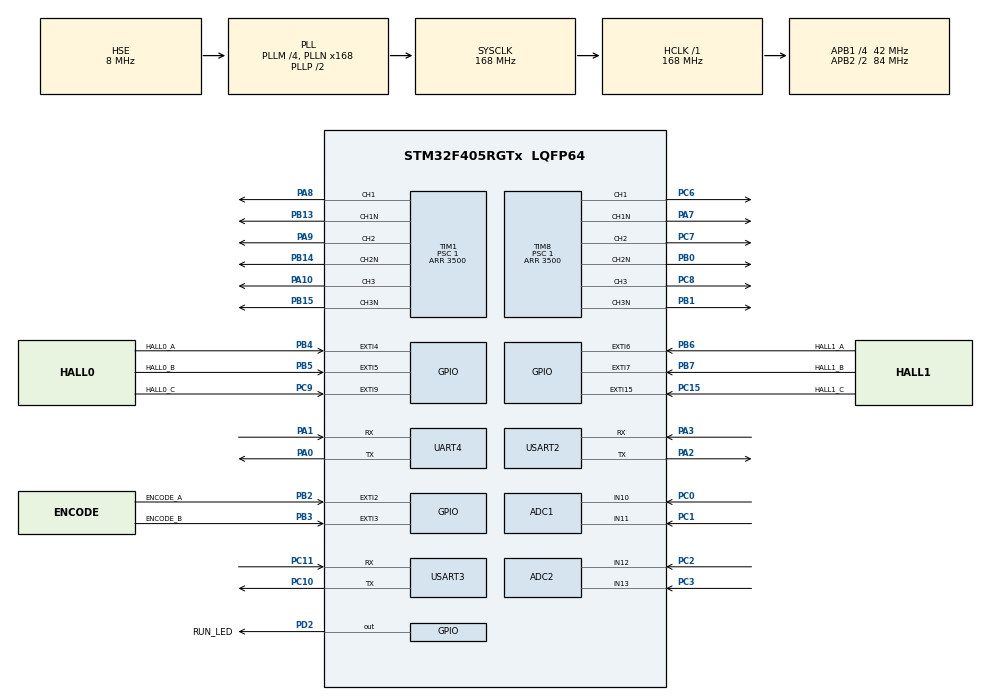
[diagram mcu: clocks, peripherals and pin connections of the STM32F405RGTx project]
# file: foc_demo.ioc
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ADC1.Channel-2\#ChannelRegularConversion=ADC_CHANNEL_10
ADC1.Channel-7\#ChannelInjectedConversion=ADC_CHANNEL_10
ADC1.Channel-8\#ChannelInjectedConversion=ADC_CHANNEL_11
ADC1.Channel-9\#ChannelRegularConversion=ADC_CHANNEL_11
ADC1.ClockPrescaler=ADC_CLOCK_SYNC_PCLK_DIV4
ADC1.DiscontinuousConvMode=ENABLE
ADC1.ExternalTrigInjecConv=ADC_EXTERNALTRIGINJECCONV_T1_CC4
ADC1.ExternalTrigInjecConvEdge=ADC_EXTERNALTRIGINJECCONVEDGE_FALLING
ADC1.InjNumberOfConversion=2
ADC1.InjectedOffset-7\#ChannelInjectedConversion=0
ADC1.InjectedOffset-8\#ChannelInjectedConversion=0
ADC1.InjectedRank-7\#ChannelInjectedConversion=1
ADC1.InjectedRank-8\#ChannelInjectedConversion=2
ADC1.NbrOfConversion=2
ADC1.NbrOfConversionFlag=1
ADC1.Rank-2\#ChannelRegularConversion=1
ADC1.Rank-9\#ChannelRegularConversion=2
ADC1.SamplingTime-2\#ChannelRegularConversion=ADC_SAMPLETIME_3CYCLES
ADC1.SamplingTime-7\#ChannelInjectedConversion=ADC_SAMPLETIME_3CYCLES
ADC1.SamplingTime-8\#ChannelInjectedConversion=ADC_SAMPLETIME_3CYCLES
ADC1.SamplingTime-9\#ChannelRegularConversion=ADC_SAMPLETIME_3CYCLES
ADC1.master=1
ADC2.Channel-0\#ChannelRegularConversion=ADC_CHANNEL_13
ADC2.Channel-4\#ChannelInjectedConversion=ADC_CHANNEL_13
ADC2.Channel-5\#ChannelInjectedConversion=ADC_CHANNEL_12
ADC2.Channel-6\#ChannelRegularConversion=ADC_CHANNEL_12
ADC2.ClockPrescaler=ADC_CLOCK_SYNC_PCLK_DIV4
ADC2.DiscontinuousConvMode=ENABLE
ADC2.ExternalTrigInjecConv=ADC_EXTERNALTRIGINJECCONV_T8_CC4
ADC2.ExternalTrigInjecConvEdge=ADC_EXTERNALTRIGINJECCONVEDGE_FALLING
ADC2.InjNumberOfConversion=2
ADC2.InjectedOffset-4\#ChannelInjectedConversion=0
ADC2.InjectedOffset-5\#ChannelInjectedConversion=0
ADC2.InjectedRank-4\#ChannelInjectedConversion=1
ADC2.InjectedRank-5\#ChannelInjectedConversion=2
ADC2.NbrOfConversion=2
ADC2.NbrOfConversionFlag=1
ADC2.Rank-0\#ChannelRegularConversion=1
ADC2.Rank-6\#ChannelRegularConversion=2
ADC2.SamplingTime-0\#ChannelRegularConversion=ADC_SAMPLETIME_3CYCLES
ADC2.SamplingTime-4\#ChannelInjectedConversion=ADC_SAMPLETIME_3CYCLES
ADC2.SamplingTime-5\#ChannelInjectedConversion=ADC_SAMPLETIME_3CYCLES
ADC2.SamplingTime-6\#ChannelRegularConversion=ADC_SAMPLETIME_3CYCLES
ADC2.ScanConvMode=ENABLE
Mcu.Family=STM32F4
Mcu.Name=STM32F405RGTx
Mcu.Package=LQFP64
NVIC.EXTI15_10_IRQn=true\:1\:0\:true\:false\:true\:true\:true\:true
NVIC.EXTI2_IRQn=true\:0\:0\:false\:false\:true\:true\:true\:true
NVIC.EXTI3_IRQn=true\:0\:0\:false\:false\:true\:true\:true\:true
NVIC.EXTI4_IRQn=true\:1\:0\:true\:false\:true\:true\:true\:true
NVIC.EXTI9_5_IRQn=true\:1\:0\:true\:false\:true\:true\:true\:true
NVIC.PriorityGroup=NVIC_PRIORITYGROUP_4
NVIC.TIM1_UP_TIM10_IRQn=true\:1\:0\:true\:false\:true\:true\:true\:true
NVIC.TIM2_IRQn=true\:1\:0\:true\:false\:true\:true\:true\:true
NVIC.TIM8_UP_TIM13_IRQn=true\:1\:0\:true\:false\:true\:true\:true\:true
NVIC.UART4_IRQn=true\:0\:0\:false\:false\:true\:true\:true\:true
NVIC.USART2_IRQn=true\:1\:0\:true\:false\:true\:true\:true\:true
NVIC.USART3_IRQn=true\:1\:0\:true\:false\:true\:true\:true\:true
PA0-WKUP.Mode=Asynchronous
PA0-WKUP.Signal=UART4_TX
PA1.Mode=Asynchronous
PA1.Signal=UART4_RX
PA10.Signal=S_TIM1_CH3
PA13.Mode=Serial_Wire
PA13.Signal=SYS_JTMS-SWDIO
PA14.Mode=Serial_Wire
PA14.Signal=SYS_JTCK-SWCLK
PA2.Mode=Asynchronous
PA2.Signal=USART2_TX
PA3.Mode=Asynchronous
PA3.Signal=USART2_RX
PA7.Mode=PWM Generation1 CH1 CH1N
PA7.Signal=TIM8_CH1N
PA8.Signal=S_TIM1_CH1
PA9.Signal=S_TIM1_CH2
PB0.Mode=PWM Generation2 CH2 CH2N
PB0.Signal=TIM8_CH2N
PB1.Mode=PWM Generation3 CH3 CH3N
PB1.Signal=TIM8_CH3N
PB13.Mode=PWM Generation1 CH1 CH1N
PB13.Signal=TIM1_CH1N
PB14.Mode=PWM Generation2 CH2 CH2N
PB14.Signal=TIM1_CH2N
PB15.Mode=PWM Generation3 CH3 CH3N
PB15.Signal=TIM1_CH3N
PB2.GPIO_Label=ENCODE_A
PB2.GPIO_ModeDefaultEXTI=GPIO_MODE_IT_RISING_FALLING
PB2.Signal=GPXTI2
PB3.GPIO_Label=ENCODE_B
PB3.GPIO_ModeDefaultEXTI=GPIO_MODE_IT_RISING_FALLING
PB3.Signal=GPXTI3
PB4.GPIO_Label=HALL0_A
PB4.GPIO_ModeDefaultEXTI=GPIO_MODE_IT_RISING_FALLING
PB4.Signal=GPXTI4
PB5.GPIO_Label=HALL0_B
PB5.GPIO_ModeDefaultEXTI=GPIO_MODE_IT_RISING_FALLING
PB5.Signal=GPXTI5
PB6.GPIO_Label=HALL1_A
PB6.GPIO_ModeDefaultEXTI=GPIO_MODE_IT_RISING_FALLING
PB6.Signal=GPXTI6
PB7.GPIO_Label=HALL1_B
PB7.GPIO_ModeDefaultEXTI=GPIO_MODE_IT_RISING_FALLING
PB7.Signal=GPXTI7
PC0.Signal=ADCx_IN10
PC1.Signal=ADCx_IN11
PC10.Mode=Asynchronous
PC10.Signal=USART3_TX
PC11.Mode=Asynchronous
PC11.Signal=USART3_RX
PC15-OSC32_OUT.GPIO_Label=HALL1_C
PC15-OSC32_OUT.GPIO_ModeDefaultEXTI=GPIO_MODE_IT_RISING_FALLING
PC15-OSC32_OUT.Signal=GPXTI15
PC2.Signal=ADCx_IN12
PC3.Signal=ADCx_IN13
PC6.Signal=S_TIM8_CH1
PC7.Signal=S_TIM8_CH2
PC8.Signal=S_TIM8_CH3
PC9.GPIO_Label=HALL0_C
PC9.GPIO_ModeDefaultEXTI=GPIO_MODE_IT_RISING_FALLING
PC9.Signal=GPXTI9
PD2.GPIO_Label=RUN_LED
PD2.GPIO_Speed=GPIO_SPEED_FREQ_VERY_HIGH
PD2.Signal=GPIO_Output
PH0-OSC_IN.Mode=HSE-External-Oscillator
PH0-OSC_IN.Signal=RCC_OSC_IN
PH1-OSC_OUT.Mode=HSE-External-Oscillator
PH1-OSC_OUT.Signal=RCC_OSC_OUT
ProjectManager.HeapSize=0x200
ProjectManager.StackSize=0x400
ProjectManager.TargetToolchain=CMake
RCC.48MHZClocksFreq_Value=84000000
RCC.AHBFreq_Value=168000000
RCC.APB1CLKDivider=RCC_HCLK_DIV4
RCC.APB1Freq_Value=42000000
RCC.APB1TimFreq_Value=84000000
RCC.APB2CLKDivider=RCC_HCLK_DIV2
RCC.APB2Freq_Value=84000000
RCC.APB2TimFreq_Value=168000000
RCC.CortexFreq_Value=168000000
RCC.HCLKFreq_Value=168000000
RCC.HSE_VALUE=8000000
RCC.HSI_VALUE=16000000
RCC.LSE_VALUE=32768
RCC.PLLM=4
RCC.PLLN=168
RCC.PLLSourceVirtual=RCC_PLLSOURCE_HSE
RCC.SYSCLKFreq_VALUE=168000000
RCC.SYSCLKSource=RCC_SYSCLKSOURCE_PLLCLK
RCC.VCOOutputFreq_Value=336000000
SH.ADCx_IN10.0=ADC1_IN10,IN10
SH.ADCx_IN11.0=ADC1_IN11,IN11
SH.ADCx_IN12.0=ADC2_IN12,IN12
SH.ADCx_IN13.0=ADC2_IN13,IN13
SH.S_TIM1_CH1.0=TIM1_CH1,PWM Generation1 CH1 CH1N
SH.S_TIM1_CH2.0=TIM1_CH2,PWM Generation2 CH2 CH2N
SH.S_TIM1_CH3.0=TIM1_CH3,PWM Generation3 CH3 CH3N
SH.S_TIM8_CH1.0=TIM8_CH1,PWM Generation1 CH1 CH1N
SH.S_TIM8_CH2.0=TIM8_CH2,PWM Generation2 CH2 CH2N
SH.S_TIM8_CH3.0=TIM8_CH3,PWM Generation3 CH3 CH3N
STMicroelectronics.X-CUBE-ALGOBUILD.1.4.0.LibraryCcDSPOoLibraryJjDSPOoLibrary=true
TIM1.AutoReloadPreload=TIM_AUTORELOAD_PRELOAD_DISABLE
TIM1.AutomaticOutput=TIM_AUTOMATICOUTPUT_DISABLE
TIM1.BreakPolarity=TIM_BREAKPOLARITY_HIGH
TIM1.Channel-PWM\ Generation1\ CH1\ CH1N=TIM_CHANNEL_1
TIM1.Channel-PWM\ Generation2\ CH2\ CH2N=TIM_CHANNEL_2
TIM1.Channel-PWM\ Generation3\ CH3\ CH3N=TIM_CHANNEL_3
TIM1.Channel-PWM\ Generation4\ No\ Output=TIM_CHANNEL_4
TIM1.ClockDivision=TIM_CLOCKDIVISION_DIV1
TIM1.CounterMode=TIM_COUNTERMODE_CENTERALIGNED1
TIM1.DeadTime=100
TIM1.LockLevel=TIM_LOCKLEVEL_1
TIM1.OCIdleState_1=TIM_OCIDLESTATE_RESET
TIM1.OCIdleState_2=TIM_OCIDLESTATE_RESET
TIM1.OCIdleState_3=TIM_OCIDLESTATE_RESET
TIM1.OCNIdleState_1=TIM_OCNIDLESTATE_SET
TIM1.OCNIdleState_2=TIM_OCNIDLESTATE_SET
TIM1.OCNIdleState_3=TIM_OCNIDLESTATE_SET
TIM1.OffStateIDLEMode=TIM_OSSI_ENABLE
TIM1.OffStateRunMode=TIM_OSSR_ENABLE
TIM1.Period=3500
TIM1.Prescaler=1
TIM1.Pulse-PWM\ Generation4\ No\ Output=3450
TIM1.RepetitionCounter=1
TIM1.TIM_MasterOutputTrigger=TIM_TRGO_RESET
TIM2.AutoReloadPreload=TIM_AUTORELOAD_PRELOAD_ENABLE
TIM2.Period=4294967295
TIM8.Channel-PWM\ Generation1\ CH1\ CH1N=TIM_CHANNEL_1
TIM8.Channel-PWM\ Generation2\ CH2\ CH2N=TIM_CHANNEL_2
TIM8.Channel-PWM\ Generation3\ CH3\ CH3N=TIM_CHANNEL_3
TIM8.Channel-PWM\ Generation4\ No\ Output=TIM_CHANNEL_4
TIM8.CounterMode=TIM_COUNTERMODE_CENTERALIGNED1
TIM8.DeadTime=100
TIM8.LockLevel=TIM_LOCKLEVEL_1
TIM8.OCNIdleState_1=TIM_OCNIDLESTATE_SET
TIM8.OCNIdleState_2=TIM_OCNIDLESTATE_SET
TIM8.OCNIdleState_3=TIM_OCNIDLESTATE_SET
TIM8.OffStateIDLEMode=TIM_OSSI_ENABLE
TIM8.OffStateRunMode=TIM_OSSR_ENABLE
TIM8.Period=3500
TIM8.Prescaler=1
TIM8.Pulse-PWM\ Generation4\ No\ Output=3450
TIM8.RepetitionCounter=1
UART4.VirtualMode=Asynchronous
USART2.VirtualMode=VM_ASYNC
USART3.VirtualMode=VM_ASYNC
VP_STMicroelectronics.X-CUBE-ALGOBUILD_VS_DSPOoLibraryJjLibrary_1.4.0_1.4.0.Mode=DSPOoLibraryJjLibrary
VP_TIM1_VS_ClockSourceINT.Mode=Internal
VP_TIM1_VS_no_output4.Mode=PWM Generation4 No Output
VP_TIM2_VS_ClockSourceINT.Mode=Internal
VP_TIM8_VS_ClockSourceINT.Mode=Internal
VP_TIM8_VS_no_output4.Mode=PWM Generation4 No Output
board=custom

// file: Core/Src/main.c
/* USER CODE BEGIN Header */
/**
  ******************************************************************************
  * @file           : main.c
  * @brief          : Main program body
  ******************************************************************************
  * @attention
  *
  * Copyright (c) 2023 STMicroelectronics.
  * All rights reserved.
  *
  * This software is licensed under terms that can be found in the LICENSE file
  * in the root directory of this software component.
  * If no LICENSE file comes with this software, it is provided AS-IS.
  *
  ******************************************************************************
  */
/* USER CODE END Header */
#include "main.h"

/* USER CODE BEGIN Includes */
#include "platform.h"
/* USER CODE END Includes */

ADC_HandleTypeDef hadc1;
ADC_HandleTypeDef hadc2;

TIM_HandleTypeDef htim1;
TIM_HandleTypeDef htim2;
TIM_HandleTypeDef htim8;

UART_HandleTypeDef huart4;
UART_HandleTypeDef huart2;
UART_HandleTypeDef huart3;

void SystemClock_Config(void);
static void MX_GPIO_Init(void);
static void MX_TIM1_Init(void);
static void MX_ADC1_Init(void);
static void MX_TIM8_Init(void);
static void MX_ADC2_Init(void);
static void MX_TIM2_Init(void);
static void MX_UART4_Init(void);
static void MX_USART2_UART_Init(void);
static void MX_USART3_UART_Init(void);

int main(void)
{

  /* MCU Configuration--------------------------------------------------------*/

  /* Reset of all peripherals, Initializes the Flash interface and the Systick. */
  HAL_Init();

  /* Configure the system clock */
  SystemClock_Config();

  /* Initialize all configured peripherals */
  MX_GPIO_Init();
  MX_TIM1_Init();
  MX_ADC1_Init();
  MX_TIM8_Init();
  MX_ADC2_Init();
  MX_TIM2_Init();
  MX_UART4_Init();
  MX_USART2_UART_Init();
  MX_USART3_UART_Init();
  /* USER CODE BEGIN 2 */
	platform_init();
  /* USER CODE END 2 */

  /* Infinite loop */
  while (1)
  {

  }
}

void SystemClock_Config(void)
{
  RCC_OscInitTypeDef RCC_OscInitStruct = {0};
  RCC_ClkInitTypeDef RCC_ClkInitStruct = {0};

  /** Configure the main internal regulator output voltage
  */
  __HAL_RCC_PWR_CLK_ENABLE();
  __HAL_PWR_VOLTAGESCALING_CONFIG(PWR_REGULATOR_VOLTAGE_SCALE1);

  /** Initializes the RCC Oscillators according to the specified parameters
  * in the RCC_OscInitTypeDef structure.
  */
  RCC_OscInitStruct.OscillatorType = RCC_OSCILLATORTYPE_HSE;
  RCC_OscInitStruct.HSEState = RCC_HSE_ON;
  RCC_OscInitStruct.PLL.PLLState = RCC_PLL_ON;
  RCC_OscInitStruct.PLL.PLLSource = RCC_PLLSOURCE_HSE;
  RCC_OscInitStruct.PLL.PLLM = 4;
  RCC_OscInitStruct.PLL.PLLN = 168;
  RCC_OscInitStruct.PLL.PLLP = RCC_PLLP_DIV2;
  RCC_OscInitStruct.PLL.PLLQ = 4;
  if (HAL_RCC_OscConfig(&RCC_OscInitStruct) != HAL_OK)
  {
    Error_Handler();
  }

  /** Initializes the CPU, AHB and APB buses clocks
  */
  RCC_ClkInitStruct.ClockType = RCC_CLOCKTYPE_HCLK|RCC_CLOCKTYPE_SYSCLK
                              |RCC_CLOCKTYPE_PCLK1|RCC_CLOCKTYPE_PCLK2;
  RCC_ClkInitStruct.SYSCLKSource = RCC_SYSCLKSOURCE_PLLCLK;
  RCC_ClkInitStruct.AHBCLKDivider = RCC_SYSCLK_DIV1;
  RCC_ClkInitStruct.APB1CLKDivider = RCC_HCLK_DIV4;
  RCC_ClkInitStruct.APB2CLKDivider = RCC_HCLK_DIV2;

  if (HAL_RCC_ClockConfig(&RCC_ClkInitStruct, FLASH_LATENCY_5) != HAL_OK)
  {
    Error_Handler();
  }
}

static void MX_ADC1_Init(void)
{

  ADC_ChannelConfTypeDef sConfig = {0};
  ADC_InjectionConfTypeDef sConfigInjected = {0};

  /** Configure the global features of the ADC (Clock, Resolution, Data Alignment and number of conversion)
  */
  hadc1.Instance = ADC1;
  hadc1.Init.ClockPrescaler = ADC_CLOCK_SYNC_PCLK_DIV4;
  hadc1.Init.Resolution = ADC_RESOLUTION_12B;
  hadc1.Init.ScanConvMode = ENABLE;
  hadc1.Init.ContinuousConvMode = DISABLE;
  hadc1.Init.DiscontinuousConvMode = ENABLE;
  hadc1.Init.NbrOfDiscConversion = 1;
  hadc1.Init.ExternalTrigConvEdge = ADC_EXTERNALTRIGCONVEDGE_NONE;
  hadc1.Init.ExternalTrigConv = ADC_SOFTWARE_START;
  hadc1.Init.DataAlign = ADC_DATAALIGN_RIGHT;
  hadc1.Init.NbrOfConversion = 2;
  hadc1.Init.DMAContinuousRequests = DISABLE;
  hadc1.Init.EOCSelection = ADC_EOC_SINGLE_CONV;
  if (HAL_ADC_Init(&hadc1) != HAL_OK)
  {
    Error_Handler();
  }

  /** Configure for the selected ADC regular channel its corresponding rank in the sequencer and its sample time.
  */
  sConfig.Channel = ADC_CHANNEL_10;
  sConfig.Rank = 1;
  sConfig.SamplingTime = ADC_SAMPLETIME_3CYCLES;
  if (HAL_ADC_ConfigChannel(&hadc1, &sConfig) != HAL_OK)
  {
    Error_Handler();
  }

  /** Configure for the selected ADC regular channel its corresponding rank in the sequencer and its sample time.
  */
  sConfig.Channel = ADC_CHANNEL_11;
  sConfig.Rank = 2;
  if (HAL_ADC_ConfigChannel(&hadc1, &sConfig) != HAL_OK)
  {
    Error_Handler();
  }

  /** Configures for the selected ADC injected channel its corresponding rank in the sequencer and its sample time
  */
  sConfigInjected.InjectedChannel = ADC_CHANNEL_10;
  sConfigInjected.InjectedRank = 1;
  sConfigInjected.InjectedNbrOfConversion = 2;
  sConfigInjected.InjectedSamplingTime = ADC_SAMPLETIME_3CYCLES;
  sConfigInjected.ExternalTrigInjecConvEdge = ADC_EXTERNALTRIGINJECCONVEDGE_FALLING;
  sConfigInjected.ExternalTrigInjecConv = ADC_EXTERNALTRIGINJECCONV_T1_CC4;
  sConfigInjected.AutoInjectedConv = DISABLE;
  sConfigInjected.InjectedDiscontinuousConvMode = DISABLE;
  sConfigInjected.InjectedOffset = 0;
  if (HAL_ADCEx_InjectedConfigChannel(&hadc1, &sConfigInjected) != HAL_OK)
  {
    Error_Handler();
  }

  /** Configures for the selected ADC injected channel its corresponding rank in the sequencer and its sample time
  */
  sConfigInjected.InjectedChannel = ADC_CHANNEL_11;
  sConfigInjected.InjectedRank = 2;
  if (HAL_ADCEx_InjectedConfigChannel(&hadc1, &sConfigInjected) != HAL_OK)
  {
    Error_Handler();
  }

}

static void MX_ADC2_Init(void)
{

  ADC_ChannelConfTypeDef sConfig = {0};
  ADC_InjectionConfTypeDef sConfigInjected = {0};

  /** Configure the global features of the ADC (Clock, Resolution, Data Alignment and number of conversion)
  */
  hadc2.Instance = ADC2;
  hadc2.Init.ClockPrescaler = ADC_CLOCK_SYNC_PCLK_DIV4;
  hadc2.Init.Resolution = ADC_RESOLUTION_12B;
  hadc2.Init.ScanConvMode = ENABLE;
  hadc2.Init.ContinuousConvMode = DISABLE;
  hadc2.Init.DiscontinuousConvMode = ENABLE;
  hadc2.Init.NbrOfDiscConversion = 1;
  hadc2.Init.ExternalTrigConvEdge = ADC_EXTERNALTRIGCONVEDGE_NONE;
  hadc2.Init.ExternalTrigConv = ADC_SOFTWARE_START;
  hadc2.Init.DataAlign = ADC_DATAALIGN_RIGHT;
  hadc2.Init.NbrOfConversion = 2;
  hadc2.Init.DMAContinuousRequests = DISABLE;
  hadc2.Init.EOCSelection = ADC_EOC_SINGLE_CONV;
  if (HAL_ADC_Init(&hadc2) != HAL_OK)
  {
    Error_Handler();
  }

  /** Configure for the selected ADC regular channel its corresponding rank in the sequencer and its sample time.
  */
  sConfig.Channel = ADC_CHANNEL_13;
  sConfig.Rank = 1;
  sConfig.SamplingTime = ADC_SAMPLETIME_3CYCLES;
  if (HAL_ADC_ConfigChannel(&hadc2, &sConfig) != HAL_OK)
  {
    Error_Handler();
  }

  /** Configure for the selected ADC regular channel its corresponding rank in the sequencer and its sample time.
  */
  sConfig.Channel = ADC_CHANNEL_12;
  sConfig.Rank = 2;
  if (HAL_ADC_ConfigChannel(&hadc2, &sConfig) != HAL_OK)
  {
    Error_Handler();
  }

  /** Configures for the selected ADC injected channel its corresponding rank in the sequencer and its sample time
  */
  sConfigInjected.InjectedChannel = ADC_CHANNEL_13;
  sConfigInjected.InjectedRank = 1;
  sConfigInjected.InjectedNbrOfConversion = 2;
  sConfigInjected.InjectedSamplingTime = ADC_SAMPLETIME_3CYCLES;
  sConfigInjected.ExternalTrigInjecConvEdge = ADC_EXTERNALTRIGINJECCONVEDGE_FALLING;
  sConfigInjected.ExternalTrigInjecConv = ADC_EXTERNALTRIGINJECCONV_T8_CC4;
  sConfigInjected.AutoInjectedConv = DISABLE;
  sConfigInjected.InjectedDiscontinuousConvMode = DISABLE;
  sConfigInjected.InjectedOffset = 0;
  if (HAL_ADCEx_InjectedConfigChannel(&hadc2, &sConfigInjected) != HAL_OK)
  {
    Error_Handler();
  }

  /** Configures for the selected ADC injected channel its corresponding rank in the sequencer and its sample time
  */
  sConfigInjected.InjectedChannel = ADC_CHANNEL_12;
  sConfigInjected.InjectedRank = 2;
  if (HAL_ADCEx_InjectedConfigChannel(&hadc2, &sConfigInjected) != HAL_OK)
  {
    Error_Handler();
  }

}

static void MX_TIM1_Init(void)
{

  TIM_ClockConfigTypeDef sClockSourceConfig = {0};
  TIM_MasterConfigTypeDef sMasterConfig = {0};
  TIM_OC_InitTypeDef sConfigOC = {0};
  TIM_BreakDeadTimeConfigTypeDef sBreakDeadTimeConfig = {0};

  htim1.Instance = TIM1;
  htim1.Init.Prescaler = 1;
  htim1.Init.CounterMode = TIM_COUNTERMODE_CENTERALIGNED1;
  htim1.Init.Period = 3500;
  htim1.Init.ClockDivision = TIM_CLOCKDIVISION_DIV1;
  htim1.Init.RepetitionCounter = 1;
  htim1.Init.AutoReloadPreload = TIM_AUTORELOAD_PRELOAD_DISABLE;
  if (HAL_TIM_Base_Init(&htim1) != HAL_OK)
  {
    Error_Handler();
  }
  sClockSourceConfig.ClockSource = TIM_CLOCKSOURCE_INTERNAL;
  if (HAL_TIM_ConfigClockSource(&htim1, &sClockSourceConfig) != HAL_OK)
  {
    Error_Handler();
  }
  if (HAL_TIM_PWM_Init(&htim1) != HAL_OK)
  {
    Error_Handler();
  }
  sMasterConfig.MasterOutputTrigger = TIM_TRGO_RESET;
  sMasterConfig.MasterSlaveMode = TIM_MASTERSLAVEMODE_DISABLE;
  if (HAL_TIMEx_MasterConfigSynchronization(&htim1, &sMasterConfig) != HAL_OK)
  {
    Error_Handler();
  }
  sConfigOC.OCMode = TIM_OCMODE_PWM1;
  sConfigOC.Pulse = 0;
  sConfigOC.OCPolarity = TIM_OCPOLARITY_HIGH;
  sConfigOC.OCNPolarity = TIM_OCNPOLARITY_HIGH;
  sConfigOC.OCFastMode = TIM_OCFAST_DISABLE;
  sConfigOC.OCIdleState = TIM_OCIDLESTATE_RESET;
  sConfigOC.OCNIdleState = TIM_OCNIDLESTATE_SET;
  if (HAL_TIM_PWM_ConfigChannel(&htim1, &sConfigOC, TIM_CHANNEL_1) != HAL_OK)
  {
    Error_Handler();
  }
  if (HAL_TIM_PWM_ConfigChannel(&htim1, &sConfigOC, TIM_CHANNEL_2) != HAL_OK)
  {
    Error_Handler();
  }
  if (HAL_TIM_PWM_ConfigChannel(&htim1, &sConfigOC, TIM_CHANNEL_3) != HAL_OK)
  {
    Error_Handler();
  }
  sConfigOC.Pulse = 3450;
  sConfigOC.OCNIdleState = TIM_OCNIDLESTATE_RESET;
  if (HAL_TIM_PWM_ConfigChannel(&htim1, &sConfigOC, TIM_CHANNEL_4) != HAL_OK)
  {
    Error_Handler();
  }
  sBreakDeadTimeConfig.OffStateRunMode = TIM_OSSR_ENABLE;
  sBreakDeadTimeConfig.OffStateIDLEMode = TIM_OSSI_ENABLE;
  sBreakDeadTimeConfig.LockLevel = TIM_LOCKLEVEL_1;
  sBreakDeadTimeConfig.DeadTime = 100;
  sBreakDeadTimeConfig.BreakState = TIM_BREAK_DISABLE;
  sBreakDeadTimeConfig.BreakPolarity = TIM_BREAKPOLARITY_HIGH;
  sBreakDeadTimeConfig.AutomaticOutput = TIM_AUTOMATICOUTPUT_DISABLE;
  if (HAL_TIMEx_ConfigBreakDeadTime(&htim1, &sBreakDeadTimeConfig) != HAL_OK)
  {
    Error_Handler();
  }
  HAL_TIM_MspPostInit(&htim1);

}

static void MX_TIM2_Init(void)
{

  TIM_ClockConfigTypeDef sClockSourceConfig = {0};
  TIM_MasterConfigTypeDef sMasterConfig = {0};

  htim2.Instance = TIM2;
  htim2.Init.Prescaler = 0;
  htim2.Init.CounterMode = TIM_COUNTERMODE_UP;
  htim2.Init.Period = 4294967295;
  htim2.Init.ClockDivision = TIM_CLOCKDIVISION_DIV1;
  htim2.Init.AutoReloadPreload = TIM_AUTORELOAD_PRELOAD_ENABLE;
  if (HAL_TIM_Base_Init(&htim2) != HAL_OK)
  {
    Error_Handler();
  }
  sClockSourceConfig.ClockSource = TIM_CLOCKSOURCE_INTERNAL;
  if (HAL_TIM_ConfigClockSource(&htim2, &sClockSourceConfig) != HAL_OK)
  {
    Error_Handler();
  }
  sMasterConfig.MasterOutputTrigger = TIM_TRGO_RESET;
  sMasterConfig.MasterSlaveMode = TIM_MASTERSLAVEMODE_DISABLE;
  if (HAL_TIMEx_MasterConfigSynchronization(&htim2, &sMasterConfig) != HAL_OK)
  {
    Error_Handler();
  }

}

static void MX_TIM8_Init(void)
{

  TIM_ClockConfigTypeDef sClockSourceConfig = {0};
  TIM_MasterConfigTypeDef sMasterConfig = {0};
  TIM_OC_InitTypeDef sConfigOC = {0};
  TIM_BreakDeadTimeConfigTypeDef sBreakDeadTimeConfig = {0};

  htim8.Instance = TIM8;
  htim8.Init.Prescaler = 1;
  htim8.Init.CounterMode = TIM_COUNTERMODE_CENTERALIGNED1;
  htim8.Init.Period = 3500;
  htim8.Init.ClockDivision = TIM_CLOCKDIVISION_DIV1;
  htim8.Init.RepetitionCounter = 1;
  htim8.Init.AutoReloadPreload = TIM_AUTORELOAD_PRELOAD_DISABLE;
  if (HAL_TIM_Base_Init(&htim8) != HAL_OK)
  {
    Error_Handler();
  }
  sClockSourceConfig.ClockSource = TIM_CLOCKSOURCE_INTERNAL;
  if (HAL_TIM_ConfigClockSource(&htim8, &sClockSourceConfig) != HAL_OK)
  {
    Error_Handler();
  }
  if (HAL_TIM_PWM_Init(&htim8) != HAL_OK)
  {
    Error_Handler();
  }
  sMasterConfig.MasterOutputTrigger = TIM_TRGO_RESET;
  sMasterConfig.MasterSlaveMode = TIM_MASTERSLAVEMODE_DISABLE;
  if (HAL_TIMEx_MasterConfigSynchronization(&htim8, &sMasterConfig) != HAL_OK)
  {
    Error_Handler();
  }
  sConfigOC.OCMode = TIM_OCMODE_PWM1;
  sConfigOC.Pulse = 0;
  sConfigOC.OCPolarity = TIM_OCPOLARITY_HIGH;
  sConfigOC.OCNPolarity = TIM_OCNPOLARITY_HIGH;
  sConfigOC.OCFastMode = TIM_OCFAST_DISABLE;
  sConfigOC.OCIdleState = TIM_OCIDLESTATE_RESET;
  sConfigOC.OCNIdleState = TIM_OCNIDLESTATE_SET;
  if (HAL_TIM_PWM_ConfigChannel(&htim8, &sConfigOC, TIM_CHANNEL_1) != HAL_OK)
  {
    Error_Handler();
  }
  if (HAL_TIM_PWM_ConfigChannel(&htim8, &sConfigOC, TIM_CHANNEL_2) != HAL_OK)
  {
    Error_Handler();
  }
  if (HAL_TIM_PWM_ConfigChannel(&htim8, &sConfigOC, TIM_CHANNEL_3) != HAL_OK)
  {
    Error_Handler();
  }
  sConfigOC.Pulse = 3450;
  sConfigOC.OCNIdleState = TIM_OCNIDLESTATE_RESET;
  if (HAL_TIM_PWM_ConfigChannel(&htim8, &sConfigOC, TIM_CHANNEL_4) != HAL_OK)
  {
    Error_Handler();
  }
  sBreakDeadTimeConfig.OffStateRunMode = TIM_OSSR_ENABLE;
  sBreakDeadTimeConfig.OffStateIDLEMode = TIM_OSSI_ENABLE;
  sBreakDeadTimeConfig.LockLevel = TIM_LOCKLEVEL_1;
  sBreakDeadTimeConfig.DeadTime = 100;
  sBreakDeadTimeConfig.BreakState = TIM_BREAK_DISABLE;
  sBreakDeadTimeConfig.BreakPolarity = TIM_BREAKPOLARITY_HIGH;
  sBreakDeadTimeConfig.AutomaticOutput = TIM_AUTOMATICOUTPUT_DISABLE;
  if (HAL_TIMEx_ConfigBreakDeadTime(&htim8, &sBreakDeadTimeConfig) != HAL_OK)
  {
    Error_Handler();
  }
  HAL_TIM_MspPostInit(&htim8);

}

static void MX_UART4_Init(void)
{

  huart4.Instance = UART4;
  huart4.Init.BaudRate = 115200;
  huart4.Init.WordLength = UART_WORDLENGTH_8B;
  huart4.Init.StopBits = UART_STOPBITS_1;
  huart4.Init.Parity = UART_PARITY_NONE;
  huart4.Init.Mode = UART_MODE_TX_RX;
  huart4.Init.HwFlowCtl = UART_HWCONTROL_NONE;
  huart4.Init.OverSampling = UART_OVERSAMPLING_16;
  if (HAL_UART_Init(&huart4) != HAL_OK)
  {
    Error_Handler();
  }

}

static void MX_USART2_UART_Init(void)
{

  huart2.Instance = USART2;
  huart2.Init.BaudRate = 115200;
  huart2.Init.WordLength = UART_WORDLENGTH_8B;
  huart2.Init.StopBits = UART_STOPBITS_1;
  huart2.Init.Parity = UART_PARITY_NONE;
  huart2.Init.Mode = UART_MODE_TX_RX;
  huart2.Init.HwFlowCtl = UART_HWCONTROL_NONE;
  huart2.Init.OverSampling = UART_OVERSAMPLING_16;
  if (HAL_UART_Init(&huart2) != HAL_OK)
  {
    Error_Handler();
  }

}

static void MX_USART3_UART_Init(void)
{

  huart3.Instance = USART3;
  huart3.Init.BaudRate = 115200;
  huart3.Init.WordLength = UART_WORDLENGTH_8B;
  huart3.Init.StopBits = UART_STOPBITS_1;
  huart3.Init.Parity = UART_PARITY_NONE;
  huart3.Init.Mode = UART_MODE_TX_RX;
  huart3.Init.HwFlowCtl = UART_HWCONTROL_NONE;
  huart3.Init.OverSampling = UART_OVERSAMPLING_16;
  if (HAL_UART_Init(&huart3) != HAL_OK)
  {
    Error_Handler();
  }

}

static void MX_GPIO_Init(void)
{
  GPIO_InitTypeDef GPIO_InitStruct = {0};

  /* GPIO Ports Clock Enable */
  __HAL_RCC_GPIOC_CLK_ENABLE();
  __HAL_RCC_GPIOH_CLK_ENABLE();
  __HAL_RCC_GPIOA_CLK_ENABLE();
  __HAL_RCC_GPIOB_CLK_ENABLE();
  __HAL_RCC_GPIOD_CLK_ENABLE();

  /*Configure GPIO pin Output Level */
  HAL_GPIO_WritePin(RUN_LED_GPIO_Port, RUN_LED_Pin, GPIO_PIN_RESET);

  /*Configure GPIO pins : HALL1_C_Pin HALL0_C_Pin */
  GPIO_InitStruct.Pin = HALL1_C_Pin|HALL0_C_Pin;
  GPIO_InitStruct.Mode = GPIO_MODE_IT_RISING_FALLING;
  GPIO_InitStruct.Pull = GPIO_NOPULL;
  HAL_GPIO_Init(GPIOC, &GPIO_InitStruct);

  /*Configure GPIO pins : ENCODE_A_Pin ENCODE_B_Pin HALL0_A_Pin HALL0_B_Pin
                           HALL1_A_Pin HALL1_B_Pin */
  GPIO_InitStruct.Pin = ENCODE_A_Pin|ENCODE_B_Pin|HALL0_A_Pin|HALL0_B_Pin
                          |HALL1_A_Pin|HALL1_B_Pin;
  GPIO_InitStruct.Mode = GPIO_MODE_IT_RISING_FALLING;
  GPIO_InitStruct.Pull = GPIO_NOPULL;
  HAL_GPIO_Init(GPIOB, &GPIO_InitStruct);

  /*Configure GPIO pin : RUN_LED_Pin */
  GPIO_InitStruct.Pin = RUN_LED_Pin;
  GPIO_InitStruct.Mode = GPIO_MODE_OUTPUT_PP;
  GPIO_InitStruct.Pull = GPIO_NOPULL;
  GPIO_InitStruct.Speed = GPIO_SPEED_FREQ_VERY_HIGH;
  HAL_GPIO_Init(RUN_LED_GPIO_Port, &GPIO_InitStruct);

  /* EXTI interrupt init*/
  HAL_NVIC_SetPriority(EXTI2_IRQn, 0, 0);
  HAL_NVIC_EnableIRQ(EXTI2_IRQn);

  HAL_NVIC_SetPriority(EXTI3_IRQn, 0, 0);
  HAL_NVIC_EnableIRQ(EXTI3_IRQn);

  HAL_NVIC_SetPriority(EXTI4_IRQn, 1, 0);
  HAL_NVIC_EnableIRQ(EXTI4_IRQn);

  HAL_NVIC_SetPriority(EXTI9_5_IRQn, 1, 0);
  HAL_NVIC_EnableIRQ(EXTI9_5_IRQn);

  HAL_NVIC_SetPriority(EXTI15_10_IRQn, 1, 0);
  HAL_NVIC_EnableIRQ(EXTI15_10_IRQn);

}

void Error_Handler(void)
{
  __disable_irq();
  while (1)
  {
  }
}
